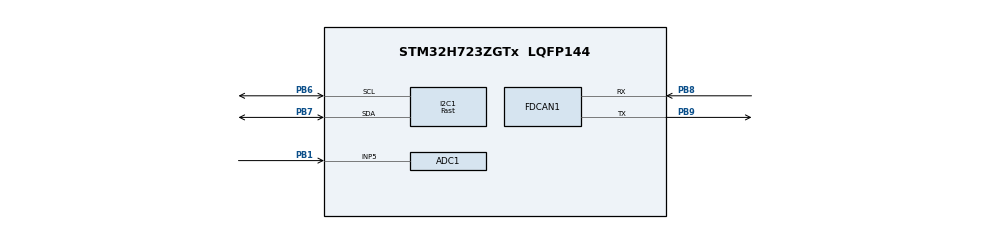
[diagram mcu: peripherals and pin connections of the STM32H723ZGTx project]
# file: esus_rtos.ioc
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ADC1.Channel-0\#ChannelRegularConversion=ADC_CHANNEL_5
ADC1.NbrOfConversionFlag=1
ADC1.OffsetNumber-0\#ChannelRegularConversion=ADC_OFFSET_NONE
ADC1.OffsetSignedSaturation-0\#ChannelRegularConversion=DISABLE
ADC1.Rank-0\#ChannelRegularConversion=1
ADC1.Resolution=ADC_RESOLUTION_16B
ADC1.SamplingTime-0\#ChannelRegularConversion=ADC_SAMPLETIME_1CYCLE_5
ADC1.master=1
CORTEX_M7.default_mode_Activation=1
FDCAN1.AutoRetransmission=ENABLE
FDCAN1.CalculateBaudRateNominal=1000000
FDCAN1.CalculateTimeBitNominal=1000
FDCAN1.CalculateTimeQuantumNominal=50.0
FDCAN1.DataPrescaler=5
FDCAN1.DataSyncJumpWidth=2
FDCAN1.DataTimeSeg1=13
FDCAN1.DataTimeSeg2=6
FDCAN1.NominalPrescaler=6
FDCAN1.NominalSyncJumpWidth=6
FDCAN1.NominalTimeSeg1=15
FDCAN1.NominalTimeSeg2=4
FDCAN1.RxFifo0ElmtsNbr=4
FDCAN1.StdFiltersNbr=1
FDCAN1.TxFifoQueueElmtsNbr=4
FREERTOS.Queues01=canTxQueue,16,uint16_t,0,Dynamic,NULL,NULL
FREERTOS.Tasks01=defaultTask,24,128,StartDefaultTask,Default,NULL,Dynamic,NULL,NULL;Sensor_Task,24,512,Start_Sensor_Read,Default,NULL,Dynamic,NULL,NULL;CAN_Tx_Task,32,256,Start_CAN_Tx,Default,NULL,Dynamic,NULL,NULL
FREERTOS.configENABLE_FPU=1
FREERTOS.configTICK_RATE_HZ=100
FREERTOS.configTOTAL_HEAP_SIZE=64000
I2C1.I2C_Speed_Mode=I2C_Fast
I2C1.Timing=0x00B03FDB
Mcu.Family=STM32H7
Mcu.Name=STM32H723ZGTx
Mcu.Package=LQFP144
NVIC.FDCAN1_IT0_IRQn=true\:5\:0\:false\:false\:true\:true\:true\:true\:true
NVIC.FDCAN1_IT1_IRQn=true\:5\:0\:false\:false\:true\:true\:true\:true\:true
NVIC.PriorityGroup=NVIC_PRIORITYGROUP_4
NVIC.TIM1_UP_IRQn=true\:15\:0\:false\:false\:true\:false\:false\:true\:true
NVIC.TimeBase=TIM1_UP_IRQn
NVIC.TimeBaseIP=TIM1
PB1.Signal=ADCx_INP5
PB6.Mode=I2C
PB6.Signal=I2C1_SCL
PB7.Mode=I2C
PB7.Signal=I2C1_SDA
PB8.Mode=FDCAN_Activate
PB8.Signal=FDCAN1_RX
PB9.Mode=FDCAN_Activate
PB9.Signal=FDCAN1_TX
ProjectManager.HeapSize=0x200
ProjectManager.StackSize=0x400
ProjectManager.TargetToolchain=CMake
RCC.ADCFreq_Value=129000000
RCC.APB1Freq_Value=120000000
RCC.APB2Freq_Value=120000000
RCC.APB3Freq_Value=120000000
RCC.APB4Freq_Value=120000000
RCC.CortexFreq_Value=480000000
RCC.D1PPRE=RCC_APB3_DIV2
RCC.D2PPRE1=RCC_APB1_DIV2
RCC.D2PPRE2=RCC_APB2_DIV2
RCC.D3PPRE=RCC_APB4_DIV2
RCC.DIVM1=4
RCC.DIVN1=30
RCC.DIVP1=1
RCC.DIVQ1=4
RCC.HCLKFreq_Value=240000000
RCC.HPRE=RCC_HCLK_DIV2
RCC.PLL2FRACN=0
RCC.PLL3FRACN=0
RCC.PLLFRACN=0
RCC.SYSCLKFreq_VALUE=480000000
RCC.SYSCLKSource=RCC_SYSCLKSOURCE_PLLCLK
RCC.USBFreq_Value=120000000
SH.ADCx_INP5.0=ADC1_INP5,IN5-Single-Ended
VP_FREERTOS_VS_CMSIS_V2.Mode=CMSIS_V2
VP_MEMORYMAP_VS_MEMORYMAP.Mode=CurAppReg
VP_SYS_VS_tim1.Mode=TIM1
board=custom

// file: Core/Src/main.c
/* USER CODE BEGIN Header */
/**
  ******************************************************************************
  * @file           : main.c
  * @brief          : Main program body
  ******************************************************************************
  * @attention
  *
  * Copyright (c) 2026 STMicroelectronics.
  * All rights reserved.
  *
  * This software is licensed under terms that can be found in the LICENSE file
  * in the root directory of this software component.
  * If no LICENSE file comes with this software, it is provided AS-IS.
  *
  ******************************************************************************
  */
/* USER CODE END Header */
#include "main.h"
#include "FreeRTOS.h"
#include "cmsis_os2.h"
#include "adc.h"
#include "fdcan.h"
#include "i2c.h"
#include "gpio.h"

void SystemClock_Config(void);
static void MPU_Config(void);
void MX_FREERTOS_Init(void);

int main(void)
{

  /* MPU Configuration--------------------------------------------------------*/
  MPU_Config();

  /* MCU Configuration--------------------------------------------------------*/

  /* Reset of all peripherals, Initializes the Flash interface and the Systick. */
  HAL_Init();

  /* Configure the system clock */
  SystemClock_Config();

  /* Initialize all configured peripherals */
  MX_GPIO_Init();
  MX_ADC1_Init();
  MX_FDCAN1_Init();
  MX_I2C1_Init();

  /* Init scheduler */
  osKernelInitialize();  /* Call init function for freertos objects (in cmsis_os2.c) */
  MX_FREERTOS_Init();

  /* Start scheduler */
  osKernelStart();

  /* We should never get here as control is now taken by the scheduler */

  /* Infinite loop */
  while (1)
  {

  }
}

void SystemClock_Config(void)
{
  RCC_OscInitTypeDef RCC_OscInitStruct = {0};
  RCC_ClkInitTypeDef RCC_ClkInitStruct = {0};

  /** Supply configuration update enable
  */
  HAL_PWREx_ConfigSupply(PWR_LDO_SUPPLY);

  /** Configure the main internal regulator output voltage
  */
  __HAL_PWR_VOLTAGESCALING_CONFIG(PWR_REGULATOR_VOLTAGE_SCALE0);

  while(!__HAL_PWR_GET_FLAG(PWR_FLAG_VOSRDY)) {}

  /** Initializes the RCC Oscillators according to the specified parameters
  * in the RCC_OscInitTypeDef structure.
  */
  RCC_OscInitStruct.OscillatorType = RCC_OSCILLATORTYPE_HSI;
  RCC_OscInitStruct.HSIState = RCC_HSI_DIV1;
  RCC_OscInitStruct.HSICalibrationValue = 64;
  RCC_OscInitStruct.PLL.PLLState = RCC_PLL_ON;
  RCC_OscInitStruct.PLL.PLLSource = RCC_PLLSOURCE_HSI;
  RCC_OscInitStruct.PLL.PLLM = 4;
  RCC_OscInitStruct.PLL.PLLN = 30;
  RCC_OscInitStruct.PLL.PLLP = 1;
  RCC_OscInitStruct.PLL.PLLQ = 4;
  RCC_OscInitStruct.PLL.PLLR = 2;
  RCC_OscInitStruct.PLL.PLLRGE = RCC_PLL1VCIRANGE_3;
  RCC_OscInitStruct.PLL.PLLVCOSEL = RCC_PLL1VCOWIDE;
  RCC_OscInitStruct.PLL.PLLFRACN = 0;
  if (HAL_RCC_OscConfig(&RCC_OscInitStruct) != HAL_OK)
  {
    Error_Handler();
  }

  /** Initializes the CPU, AHB and APB buses clocks
  */
  RCC_ClkInitStruct.ClockType = RCC_CLOCKTYPE_HCLK|RCC_CLOCKTYPE_SYSCLK
                              |RCC_CLOCKTYPE_PCLK1|RCC_CLOCKTYPE_PCLK2
                              |RCC_CLOCKTYPE_D3PCLK1|RCC_CLOCKTYPE_D1PCLK1;
  RCC_ClkInitStruct.SYSCLKSource = RCC_SYSCLKSOURCE_PLLCLK;
  RCC_ClkInitStruct.SYSCLKDivider = RCC_SYSCLK_DIV1;
  RCC_ClkInitStruct.AHBCLKDivider = RCC_HCLK_DIV2;
  RCC_ClkInitStruct.APB3CLKDivider = RCC_APB3_DIV2;
  RCC_ClkInitStruct.APB1CLKDivider = RCC_APB1_DIV2;
  RCC_ClkInitStruct.APB2CLKDivider = RCC_APB2_DIV2;
  RCC_ClkInitStruct.APB4CLKDivider = RCC_APB4_DIV2;

  if (HAL_RCC_ClockConfig(&RCC_ClkInitStruct, FLASH_LATENCY_3) != HAL_OK)
  {
    Error_Handler();
  }
}

 /* MPU Configuration */

void MPU_Config(void)
{
  MPU_Region_InitTypeDef MPU_InitStruct = {0};

  /* Disables the MPU */
  HAL_MPU_Disable();

  /** Initializes and configures the Region and the memory to be protected
  */
  MPU_InitStruct.Enable = MPU_REGION_ENABLE;
  MPU_InitStruct.Number = MPU_REGION_NUMBER0;
  MPU_InitStruct.BaseAddress = 0x0;
  MPU_InitStruct.Size = MPU_REGION_SIZE_4GB;
  MPU_InitStruct.SubRegionDisable = 0x87;
  MPU_InitStruct.TypeExtField = MPU_TEX_LEVEL0;
  MPU_InitStruct.AccessPermission = MPU_REGION_NO_ACCESS;
  MPU_InitStruct.DisableExec = MPU_INSTRUCTION_ACCESS_DISABLE;
  MPU_InitStruct.IsShareable = MPU_ACCESS_SHAREABLE;
  MPU_InitStruct.IsCacheable = MPU_ACCESS_NOT_CACHEABLE;
  MPU_InitStruct.IsBufferable = MPU_ACCESS_NOT_BUFFERABLE;

  HAL_MPU_ConfigRegion(&MPU_InitStruct);
  /* Enables the MPU */
  HAL_MPU_Enable(MPU_PRIVILEGED_DEFAULT);

}

void HAL_TIM_PeriodElapsedCallback(TIM_HandleTypeDef *htim)
{
  if (htim->Instance == TIM1)
  {
    HAL_IncTick();
  }
}

void Error_Handler(void)
{
  __disable_irq();
  while (1)
  {
  }
}

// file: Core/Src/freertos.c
/* USER CODE BEGIN Header */
/**
  ******************************************************************************
  * File Name          : freertos.c
  * Description        : Code for freertos applications
  ******************************************************************************
  * @attention
  *
  * Copyright (c) 2026 STMicroelectronics.
  * All rights reserved.
  *
  * This software is licensed under terms that can be found in the LICENSE file
  * in the root directory of this software component.
  * If no LICENSE file comes with this software, it is provided AS-IS.
  *
  ******************************************************************************
  */
/* USER CODE END Header */

/* USER CODE BEGIN Includes */
#include "FreeRTOS.h"
#include "task.h"
#include "main.h"
#include "FreeRTOS.h"
#include "cmsis_os2.h"
#include "control.h"
/* USER CODE END Includes */

/* Definitions for defaultTask */
osThreadId_t defaultTaskHandle;
const osThreadAttr_t defaultTask_attributes = {
  .name = "defaultTask",
  .stack_size = 128 * 4,
  .priority = (osPriority_t) osPriorityNormal,
};
/* Definitions for Sensor_Task */
osThreadId_t Sensor_TaskHandle;
const osThreadAttr_t Sensor_Task_attributes = {
  .name = "Sensor_Task",
  .stack_size = 512 * 4,
  .priority = (osPriority_t) osPriorityNormal,
};
/* Definitions for CAN_Tx_Task */
osThreadId_t CAN_Tx_TaskHandle;
const osThreadAttr_t CAN_Tx_Task_attributes = {
  .name = "CAN_Tx_Task",
  .stack_size = 256 * 4,
  .priority = (osPriority_t) osPriorityAboveNormal,
};
/* Definitions for canTxQueue */
osMessageQueueId_t canTxQueueHandle;
const osMessageQueueAttr_t canTxQueue_attributes = {
  .name = "canTxQueue"
};

void StartDefaultTask(void *argument);
void Start_Sensor_Read(void *argument);
void Start_CAN_Tx(void *argument);

void MX_FREERTOS_Init(void); /* (MISRA C 2004 rule 8.1) */

void MX_FREERTOS_Init(void) {

  /* Create the queue(s) */
  /* creation of canTxQueue */
  canTxQueueHandle = osMessageQueueNew (16, sizeof(uint16_t), &canTxQueue_attributes);

  /* Create the thread(s) */
  /* creation of defaultTask */
  defaultTaskHandle = osThreadNew(StartDefaultTask, NULL, &defaultTask_attributes);

  /* creation of Sensor_Task */
  Sensor_TaskHandle = osThreadNew(Start_Sensor_Read, NULL, &Sensor_Task_attributes);

  /* creation of CAN_Tx_Task */
  CAN_Tx_TaskHandle = osThreadNew(Start_CAN_Tx, NULL, &CAN_Tx_Task_attributes);

}

void StartDefaultTask(void *argument)
{
  for(;;)
  {
    osDelay(1);
  }
}

void Start_Sensor_Read(void *argument)
{
  /* USER CODE BEGIN Start_Sensor_Read */
  /* Infinite loop */
  for(;;)
  {
    TelemetryPayload_t telemetry_payload;
    Prep_IMU_For_CAN(&telemetry_payload);
    Prep_LinPot_For_CAN(&telemetry_payload);
    Transmit_Telemetry(&telemetry_payload, CAN_ID_ESUS_FL);
    osDelay(10);
  }
  /* USER CODE END Start_Sensor_Read */
}

void Start_CAN_Tx(void *argument)
{
  for(;;)
  {
    osDelay(1);
  }
}
